# COMPUTE_CLUSTER_J7AHP0_MSMC_ECC_AGGR0_0_VBUSP_MSMC_ECC_AGGR0_CFG_MSMC_ECC0 register map
Vendor: Texas Instruments
Peripheral module from a debugger description file (folder J7_AHP).
Registers are 32-bit, access not given, reset 0x0 unless marked. A register's access mark holds for its fields unless they carry their own. Offsets are as the file gives them; lines under a group give offsets from that group; [hi:lo] are bit positions; {n}, {i} and the like mark numbered series; 'fields as' and 'values as' point back to an identical list; <NAME> marks a mode.

## COMPUTE_CLUSTER_J7AHP0_MSMC_ECC_AGGR0_0_VBUSP_MSMC_ECC_AGGR0_CFG_MSMC_ECC0
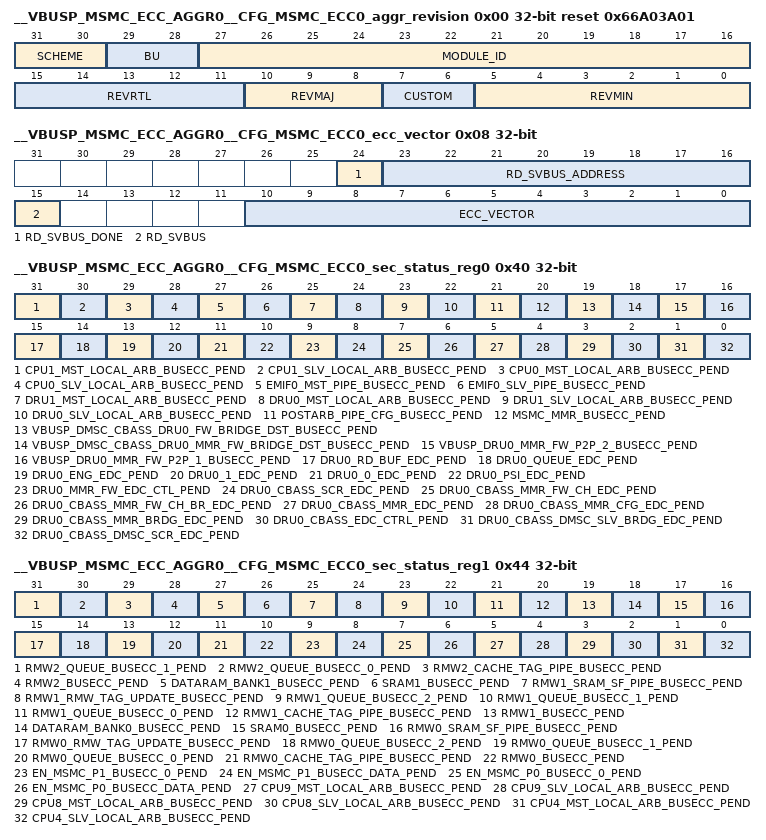
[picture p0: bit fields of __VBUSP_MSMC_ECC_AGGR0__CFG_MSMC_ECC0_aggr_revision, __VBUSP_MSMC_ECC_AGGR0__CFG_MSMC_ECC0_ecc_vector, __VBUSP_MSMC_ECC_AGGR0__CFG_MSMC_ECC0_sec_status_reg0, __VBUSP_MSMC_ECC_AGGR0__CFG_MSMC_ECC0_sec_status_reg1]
0x00 __VBUSP_MSMC_ECC_AGGR0__CFG_MSMC_ECC0_aggr_revision ro reset 0x66A03A01
  [31:30] SCHEME
  [29:28] BU
  [27:16] MODULE_ID
  [15:11] REVRTL — RTL version
  [10:8] REVMAJ — Major version
  [7:6] CUSTOM — Custom version
  [5:0] REVMIN — Minor version
0x08 __VBUSP_MSMC_ECC_AGGR0__CFG_MSMC_ECC0_ecc_vector
  [24] RD_SVBUS_DONE — Status to indicate if read on serial VBUS is complete, write of any value will clear this bit. (access R/W1TC)
  [23:16] RD_SVBUS_ADDRESS rw — Read address
  [15] RD_SVBUS — Write 1 to trigger a read on the serial VBUS (access R/W1TS)
  [10:0] ECC_VECTOR rw — Value written to select the corresponding ECC RAM for control or status
0x0C __VBUSP_MSMC_ECC_AGGR0__CFG_MSMC_ECC0_misc_status ro reset 0x83
  [10:0] NUM_RAMS — Indicates the number of RAMS serviced by the ECC aggregator
0x10 __VBUSP_MSMC_ECC_AGGR0__CFG_MSMC_ECC0_reserved_svbus rw
  [31:0] DATA — Serial VBUS register data
0x3C __VBUSP_MSMC_ECC_AGGR0__CFG_MSMC_ECC0_sec_eoi_reg
  [0] EOI_WR — EOI Register (access R/W1TS)
0x40 __VBUSP_MSMC_ECC_AGGR0__CFG_MSMC_ECC0_sec_status_reg0
  [31] CPU1_MST_LOCAL_ARB_BUSECC_PEND — Interrupt Pending Status for cpu1_mst_local_arb_busecc_pend (access R/W1TS)
  [30] CPU1_SLV_LOCAL_ARB_BUSECC_PEND — Interrupt Pending Status for cpu1_slv_local_arb_busecc_pend (access R/W1TS)
  [29] CPU0_MST_LOCAL_ARB_BUSECC_PEND — Interrupt Pending Status for cpu0_mst_local_arb_busecc_pend (access R/W1TS)
  [28] CPU0_SLV_LOCAL_ARB_BUSECC_PEND — Interrupt Pending Status for cpu0_slv_local_arb_busecc_pend (access R/W1TS)
  [27] EMIF0_MST_PIPE_BUSECC_PEND — Interrupt Pending Status for emif0_mst_pipe_busecc_pend (access R/W1TS)
  [26] EMIF0_SLV_PIPE_BUSECC_PEND — Interrupt Pending Status for emif0_slv_pipe_busecc_pend (access R/W1TS)
  [25] DRU1_MST_LOCAL_ARB_BUSECC_PEND — Interrupt Pending Status for dru1_mst_local_arb_busecc_pend (access R/W1TS)
  [24] DRU0_MST_LOCAL_ARB_BUSECC_PEND — Interrupt Pending Status for dru0_mst_local_arb_busecc_pend (access R/W1TS)
  [23] DRU1_SLV_LOCAL_ARB_BUSECC_PEND — Interrupt Pending Status for dru1_slv_local_arb_busecc_pend (access R/W1TS)
  [22] DRU0_SLV_LOCAL_ARB_BUSECC_PEND — Interrupt Pending Status for dru0_slv_local_arb_busecc_pend (access R/W1TS)
  [21] POSTARB_PIPE_CFG_BUSECC_PEND — Interrupt Pending Status for postarb_pipe_cfg_busecc_pend (access R/W1TS)
  [20] MSMC_MMR_BUSECC_PEND — Interrupt Pending Status for msmc_mmr_busecc_pend (access R/W1TS)
  [19] VBUSP_DMSC_CBASS_DRU0_FW_BRIDGE_DST_BUSECC_PEND — Interrupt Pending Status for vbusp_dmsc_cbass_dru0_fw_bridge_dst_busecc_pend (access R/W1TS)
  [18] VBUSP_DMSC_CBASS_DRU0_MMR_FW_BRIDGE_DST_BUSECC_PEND — Interrupt Pending Status for vbusp_dmsc_cbass_dru0_mmr_fw_bridge_dst_busecc_pend (access R/W1TS)
  [17] VBUSP_DRU0_MMR_FW_P2P_2_BUSECC_PEND — Interrupt Pending Status for vbusp_dru0_mmr_fw_p2p_2_busecc_pend (access R/W1TS)
  [16] VBUSP_DRU0_MMR_FW_P2P_1_BUSECC_PEND — Interrupt Pending Status for vbusp_dru0_mmr_fw_p2p_1_busecc_pend (access R/W1TS)
  [15] DRU0_RD_BUF_EDC_PEND — Interrupt Pending Status for dru0_rd_buf_edc_pend (access R/W1TS)
  [14] DRU0_QUEUE_EDC_PEND — Interrupt Pending Status for dru0_queue_edc_pend (access R/W1TS)
  [13] DRU0_ENG_EDC_PEND — Interrupt Pending Status for dru0_eng_edc_pend (access R/W1TS)
  [12] DRU0_1_EDC_PEND — Interrupt Pending Status for dru0_1_edc_pend (access R/W1TS)
  [11] DRU0_0_EDC_PEND — Interrupt Pending Status for dru0_0_edc_pend (access R/W1TS)
  [10] DRU0_PSI_EDC_PEND — Interrupt Pending Status for dru0_psi_edc_pend (access R/W1TS)
  [9] DRU0_MMR_FW_EDC_CTL_PEND — Interrupt Pending Status for dru0_mmr_fw_edc_ctl_pend (access R/W1TS)
  [8] DRU0_CBASS_SCR_EDC_PEND — Interrupt Pending Status for dru0_cbass_scr_edc_pend (access R/W1TS)
  [7] DRU0_CBASS_MMR_FW_CH_EDC_PEND — Interrupt Pending Status for dru0_cbass_mmr_fw_ch_edc_pend (access R/W1TS)
  [6] DRU0_CBASS_MMR_FW_CH_BR_EDC_PEND — Interrupt Pending Status for dru0_cbass_mmr_fw_ch_br_edc_pend (access R/W1TS)
  [5] DRU0_CBASS_MMR_EDC_PEND — Interrupt Pending Status for dru0_cbass_mmr_edc_pend (access R/W1TS)
  [4] DRU0_CBASS_MMR_CFG_EDC_PEND — Interrupt Pending Status for dru0_cbass_mmr_cfg_edc_pend (access R/W1TS)
  [3] DRU0_CBASS_MMR_BRDG_EDC_PEND — Interrupt Pending Status for dru0_cbass_mmr_brdg_edc_pend (access R/W1TS)
  [2] DRU0_CBASS_EDC_CTRL_PEND — Interrupt Pending Status for dru0_cbass_edc_ctrl_pend (access R/W1TS)
  [1] DRU0_CBASS_DMSC_SLV_BRDG_EDC_PEND — Interrupt Pending Status for dru0_cbass_dmsc_slv_brdg_edc_pend (access R/W1TS)
  [0] DRU0_CBASS_DMSC_SCR_EDC_PEND — Interrupt Pending Status for dru0_cbass_dmsc_scr_edc_pend (access R/W1TS)
0x44 __VBUSP_MSMC_ECC_AGGR0__CFG_MSMC_ECC0_sec_status_reg1
  [31] RMW2_QUEUE_BUSECC_1_PEND — Interrupt Pending Status for rmw2_queue_busecc_1_pend (access R/W1TS)
  [30] RMW2_QUEUE_BUSECC_0_PEND — Interrupt Pending Status for rmw2_queue_busecc_0_pend (access R/W1TS)
  [29] RMW2_CACHE_TAG_PIPE_BUSECC_PEND — Interrupt Pending Status for rmw2_cache_tag_pipe_busecc_pend (access R/W1TS)
  [28] RMW2_BUSECC_PEND — Interrupt Pending Status for rmw2_busecc_pend (access R/W1TS)
  [27] DATARAM_BANK1_BUSECC_PEND — Interrupt Pending Status for dataram_bank1_busecc_pend (access R/W1TS)
  [26] SRAM1_BUSECC_PEND — Interrupt Pending Status for sram1_busecc_pend (access R/W1TS)
  [25] RMW1_SRAM_SF_PIPE_BUSECC_PEND — Interrupt Pending Status for rmw1_sram_sf_pipe_busecc_pend (access R/W1TS)
  [24] RMW1_RMW_TAG_UPDATE_BUSECC_PEND — Interrupt Pending Status for rmw1_rmw_tag_update_busecc_pend (access R/W1TS)
  [23] RMW1_QUEUE_BUSECC_2_PEND — Interrupt Pending Status for rmw1_queue_busecc_2_pend (access R/W1TS)
  [22] RMW1_QUEUE_BUSECC_1_PEND — Interrupt Pending Status for rmw1_queue_busecc_1_pend (access R/W1TS)
  [21] RMW1_QUEUE_BUSECC_0_PEND — Interrupt Pending Status for rmw1_queue_busecc_0_pend (access R/W1TS)
  [20] RMW1_CACHE_TAG_PIPE_BUSECC_PEND — Interrupt Pending Status for rmw1_cache_tag_pipe_busecc_pend (access R/W1TS)
  [19] RMW1_BUSECC_PEND — Interrupt Pending Status for rmw1_busecc_pend (access R/W1TS)
  [18] DATARAM_BANK0_BUSECC_PEND — Interrupt Pending Status for dataram_bank0_busecc_pend (access R/W1TS)
  [17] SRAM0_BUSECC_PEND — Interrupt Pending Status for sram0_busecc_pend (access R/W1TS)
  [16] RMW0_SRAM_SF_PIPE_BUSECC_PEND — Interrupt Pending Status for rmw0_sram_sf_pipe_busecc_pend (access R/W1TS)
  [15] RMW0_RMW_TAG_UPDATE_BUSECC_PEND — Interrupt Pending Status for rmw0_rmw_tag_update_busecc_pend (access R/W1TS)
  [14] RMW0_QUEUE_BUSECC_2_PEND — Interrupt Pending Status for rmw0_queue_busecc_2_pend (access R/W1TS)
  [13] RMW0_QUEUE_BUSECC_1_PEND — Interrupt Pending Status for rmw0_queue_busecc_1_pend (access R/W1TS)
  [12] RMW0_QUEUE_BUSECC_0_PEND — Interrupt Pending Status for rmw0_queue_busecc_0_pend (access R/W1TS)
  [11] RMW0_CACHE_TAG_PIPE_BUSECC_PEND — Interrupt Pending Status for rmw0_cache_tag_pipe_busecc_pend (access R/W1TS)
  [10] RMW0_BUSECC_PEND — Interrupt Pending Status for rmw0_busecc_pend (access R/W1TS)
  [9] EN_MSMC_P1_BUSECC_0_PEND — Interrupt Pending Status for en_msmc_p1_busecc_0_pend (access R/W1TS)
  [8] EN_MSMC_P1_BUSECC_DATA_PEND — Interrupt Pending Status for en_msmc_p1_busecc_data_pend (access R/W1TS)
  [7] EN_MSMC_P0_BUSECC_0_PEND — Interrupt Pending Status for en_msmc_p0_busecc_0_pend (access R/W1TS)
  [6] EN_MSMC_P0_BUSECC_DATA_PEND — Interrupt Pending Status for en_msmc_p0_busecc_data_pend (access R/W1TS)
  [5] CPU9_MST_LOCAL_ARB_BUSECC_PEND — Interrupt Pending Status for cpu9_mst_local_arb_busecc_pend (access R/W1TS)
  [4] CPU9_SLV_LOCAL_ARB_BUSECC_PEND — Interrupt Pending Status for cpu9_slv_local_arb_busecc_pend (access R/W1TS)
  [3] CPU8_MST_LOCAL_ARB_BUSECC_PEND — Interrupt Pending Status for cpu8_mst_local_arb_busecc_pend (access R/W1TS)
  [2] CPU8_SLV_LOCAL_ARB_BUSECC_PEND — Interrupt Pending Status for cpu8_slv_local_arb_busecc_pend (access R/W1TS)
  [1] CPU4_MST_LOCAL_ARB_BUSECC_PEND — Interrupt Pending Status for cpu4_mst_local_arb_busecc_pend (access R/W1TS)
  [0] CPU4_SLV_LOCAL_ARB_BUSECC_PEND — Interrupt Pending Status for cpu4_slv_local_arb_busecc_pend (access R/W1TS)
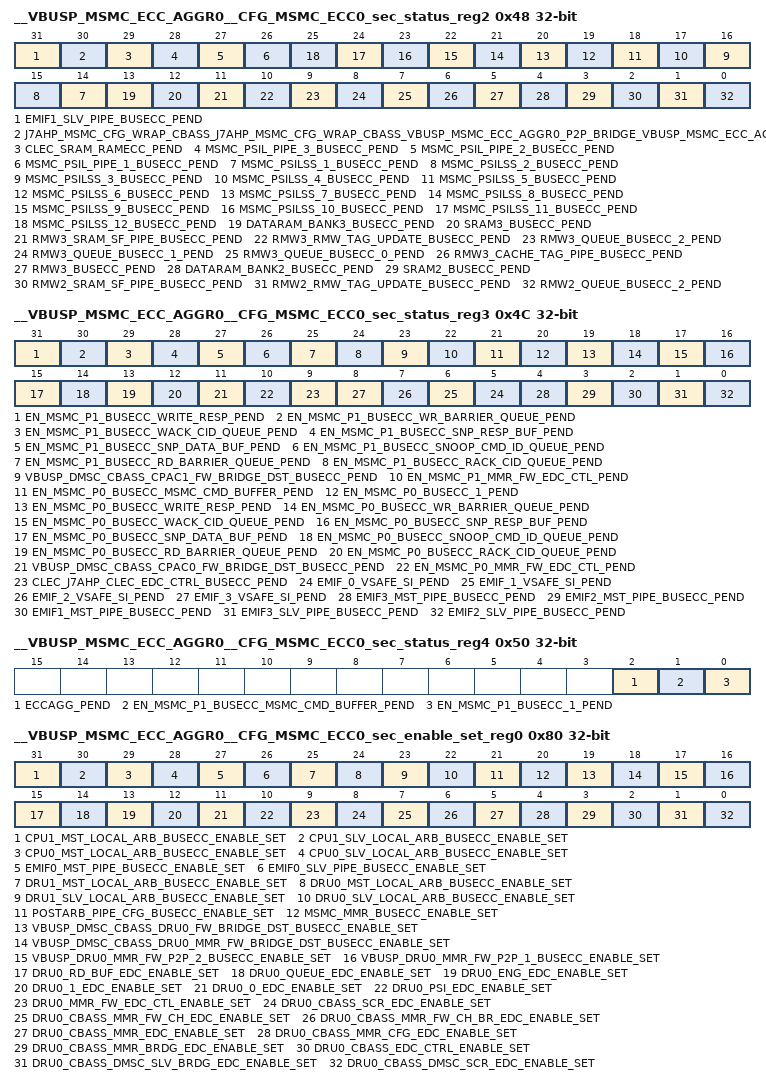
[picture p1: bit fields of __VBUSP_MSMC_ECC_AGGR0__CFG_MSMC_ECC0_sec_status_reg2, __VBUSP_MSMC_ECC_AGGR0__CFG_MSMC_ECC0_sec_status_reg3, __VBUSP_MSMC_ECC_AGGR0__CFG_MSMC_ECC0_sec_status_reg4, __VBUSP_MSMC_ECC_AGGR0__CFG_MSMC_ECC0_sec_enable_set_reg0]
0x48 __VBUSP_MSMC_ECC_AGGR0__CFG_MSMC_ECC0_sec_status_reg2
  [31] EMIF1_SLV_PIPE_BUSECC_PEND — Interrupt Pending Status for emif1_slv_pipe_busecc_pend (access R/W1TS)
  [30] J7AHP_MSMC_CFG_WRAP_CBASS_J7AHP_MSMC_CFG_WRAP_CBASS_VBUSP_MSMC_ECC_AGGR0_P2P_BRIDGE_VBUSP_MSMC_ECC_AGGR0_BRIDGE_DST_BUSECC_PEND — Interrupt Pending Status for j7ahp_msmc_cfg_wrap_cbass_j7ahp_msmc_cfg_wrap_cbass_vbusp_msmc_ecc_aggr0_p2p_bridge_vbusp_msmc_ecc_aggr0_bridge_dst_busecc_pend (access R/W1TS)
  [29] CLEC_SRAM_RAMECC_PEND — Interrupt Pending Status for clec_sram_ramecc_pend (access R/W1TS)
  [28] MSMC_PSIL_PIPE_3_BUSECC_PEND — Interrupt Pending Status for msmc_psil_pipe_3_busecc_pend (access R/W1TS)
  [27] MSMC_PSIL_PIPE_2_BUSECC_PEND — Interrupt Pending Status for msmc_psil_pipe_2_busecc_pend (access R/W1TS)
  [26] MSMC_PSIL_PIPE_1_BUSECC_PEND — Interrupt Pending Status for msmc_psil_pipe_1_busecc_pend (access R/W1TS)
  [n+13] MSMC_PSILSS_{n}_BUSECC_PEND (n=1..12) — Interrupt Pending Status for msmc_psilss_{n}_busecc_pend (access R/W1TS)
  [13] DATARAM_BANK3_BUSECC_PEND — Interrupt Pending Status for dataram_bank3_busecc_pend (access R/W1TS)
  [12] SRAM3_BUSECC_PEND — Interrupt Pending Status for sram3_busecc_pend (access R/W1TS)
  [11] RMW3_SRAM_SF_PIPE_BUSECC_PEND — Interrupt Pending Status for rmw3_sram_sf_pipe_busecc_pend (access R/W1TS)
  [10] RMW3_RMW_TAG_UPDATE_BUSECC_PEND — Interrupt Pending Status for rmw3_rmw_tag_update_busecc_pend (access R/W1TS)
  [9] RMW3_QUEUE_BUSECC_2_PEND — Interrupt Pending Status for rmw3_queue_busecc_2_pend (access R/W1TS)
  [8] RMW3_QUEUE_BUSECC_1_PEND — Interrupt Pending Status for rmw3_queue_busecc_1_pend (access R/W1TS)
  [7] RMW3_QUEUE_BUSECC_0_PEND — Interrupt Pending Status for rmw3_queue_busecc_0_pend (access R/W1TS)
  [6] RMW3_CACHE_TAG_PIPE_BUSECC_PEND — Interrupt Pending Status for rmw3_cache_tag_pipe_busecc_pend (access R/W1TS)
  [5] RMW3_BUSECC_PEND — Interrupt Pending Status for rmw3_busecc_pend (access R/W1TS)
  [4] DATARAM_BANK2_BUSECC_PEND — Interrupt Pending Status for dataram_bank2_busecc_pend (access R/W1TS)
  [3] SRAM2_BUSECC_PEND — Interrupt Pending Status for sram2_busecc_pend (access R/W1TS)
  [2] RMW2_SRAM_SF_PIPE_BUSECC_PEND — Interrupt Pending Status for rmw2_sram_sf_pipe_busecc_pend (access R/W1TS)
  [1] RMW2_RMW_TAG_UPDATE_BUSECC_PEND — Interrupt Pending Status for rmw2_rmw_tag_update_busecc_pend (access R/W1TS)
  [0] RMW2_QUEUE_BUSECC_2_PEND — Interrupt Pending Status for rmw2_queue_busecc_2_pend (access R/W1TS)
0x4C __VBUSP_MSMC_ECC_AGGR0__CFG_MSMC_ECC0_sec_status_reg3
  [31] EN_MSMC_P1_BUSECC_WRITE_RESP_PEND — Interrupt Pending Status for en_msmc_p1_busecc_write_resp_pend (access R/W1TS)
  [30] EN_MSMC_P1_BUSECC_WR_BARRIER_QUEUE_PEND — Interrupt Pending Status for en_msmc_p1_busecc_wr_barrier_queue_pend (access R/W1TS)
  [29] EN_MSMC_P1_BUSECC_WACK_CID_QUEUE_PEND — Interrupt Pending Status for en_msmc_p1_busecc_wack_cid_queue_pend (access R/W1TS)
  [28] EN_MSMC_P1_BUSECC_SNP_RESP_BUF_PEND — Interrupt Pending Status for en_msmc_p1_busecc_snp_resp_buf_pend (access R/W1TS)
  [27] EN_MSMC_P1_BUSECC_SNP_DATA_BUF_PEND — Interrupt Pending Status for en_msmc_p1_busecc_snp_data_buf_pend (access R/W1TS)
  [26] EN_MSMC_P1_BUSECC_SNOOP_CMD_ID_QUEUE_PEND — Interrupt Pending Status for en_msmc_p1_busecc_snoop_cmd_id_queue_pend (access R/W1TS)
  [25] EN_MSMC_P1_BUSECC_RD_BARRIER_QUEUE_PEND — Interrupt Pending Status for en_msmc_p1_busecc_rd_barrier_queue_pend (access R/W1TS)
  [24] EN_MSMC_P1_BUSECC_RACK_CID_QUEUE_PEND — Interrupt Pending Status for en_msmc_p1_busecc_rack_cid_queue_pend (access R/W1TS)
  [23] VBUSP_DMSC_CBASS_CPAC1_FW_BRIDGE_DST_BUSECC_PEND — Interrupt Pending Status for vbusp_dmsc_cbass_cpac1_fw_bridge_dst_busecc_pend (access R/W1TS)
  [22] EN_MSMC_P1_MMR_FW_EDC_CTL_PEND — Interrupt Pending Status for en_msmc_p1_mmr_fw_edc_ctl_pend (access R/W1TS)
  [21] EN_MSMC_P0_BUSECC_MSMC_CMD_BUFFER_PEND — Interrupt Pending Status for en_msmc_p0_busecc_msmc_cmd_buffer_pend (access R/W1TS)
  [20] EN_MSMC_P0_BUSECC_1_PEND — Interrupt Pending Status for en_msmc_p0_busecc_1_pend (access R/W1TS)
  [19] EN_MSMC_P0_BUSECC_WRITE_RESP_PEND — Interrupt Pending Status for en_msmc_p0_busecc_write_resp_pend (access R/W1TS)
  [18] EN_MSMC_P0_BUSECC_WR_BARRIER_QUEUE_PEND — Interrupt Pending Status for en_msmc_p0_busecc_wr_barrier_queue_pend (access R/W1TS)
  [17] EN_MSMC_P0_BUSECC_WACK_CID_QUEUE_PEND — Interrupt Pending Status for en_msmc_p0_busecc_wack_cid_queue_pend (access R/W1TS)
  [16] EN_MSMC_P0_BUSECC_SNP_RESP_BUF_PEND — Interrupt Pending Status for en_msmc_p0_busecc_snp_resp_buf_pend (access R/W1TS)
  [15] EN_MSMC_P0_BUSECC_SNP_DATA_BUF_PEND — Interrupt Pending Status for en_msmc_p0_busecc_snp_data_buf_pend (access R/W1TS)
  [14] EN_MSMC_P0_BUSECC_SNOOP_CMD_ID_QUEUE_PEND — Interrupt Pending Status for en_msmc_p0_busecc_snoop_cmd_id_queue_pend (access R/W1TS)
  [13] EN_MSMC_P0_BUSECC_RD_BARRIER_QUEUE_PEND — Interrupt Pending Status for en_msmc_p0_busecc_rd_barrier_queue_pend (access R/W1TS)
  [12] EN_MSMC_P0_BUSECC_RACK_CID_QUEUE_PEND — Interrupt Pending Status for en_msmc_p0_busecc_rack_cid_queue_pend (access R/W1TS)
  [11] VBUSP_DMSC_CBASS_CPAC0_FW_BRIDGE_DST_BUSECC_PEND — Interrupt Pending Status for vbusp_dmsc_cbass_cpac0_fw_bridge_dst_busecc_pend (access R/W1TS)
  [10] EN_MSMC_P0_MMR_FW_EDC_CTL_PEND — Interrupt Pending Status for en_msmc_p0_mmr_fw_edc_ctl_pend (access R/W1TS)
  [9] CLEC_J7AHP_CLEC_EDC_CTRL_BUSECC_PEND — Interrupt Pending Status for clec_j7ahp_clec_edc_ctrl_busecc_pend (access R/W1TS)
  [n+5] EMIF_{n}_VSAFE_SI_PEND (n=0..3) — Interrupt Pending Status for emif_{n}_vsafe_si_pend (access R/W1TS)
  [4] EMIF3_MST_PIPE_BUSECC_PEND — Interrupt Pending Status for emif3_mst_pipe_busecc_pend (access R/W1TS)
  [3] EMIF2_MST_PIPE_BUSECC_PEND — Interrupt Pending Status for emif2_mst_pipe_busecc_pend (access R/W1TS)
  [2] EMIF1_MST_PIPE_BUSECC_PEND — Interrupt Pending Status for emif1_mst_pipe_busecc_pend (access R/W1TS)
  [1] EMIF3_SLV_PIPE_BUSECC_PEND — Interrupt Pending Status for emif3_slv_pipe_busecc_pend (access R/W1TS)
  [0] EMIF2_SLV_PIPE_BUSECC_PEND — Interrupt Pending Status for emif2_slv_pipe_busecc_pend (access R/W1TS)
0x50 __VBUSP_MSMC_ECC_AGGR0__CFG_MSMC_ECC0_sec_status_reg4
  [2] ECCAGG_PEND — Interrupt Pending Status for eccagg_pend (access R/W1TS)
  [1] EN_MSMC_P1_BUSECC_MSMC_CMD_BUFFER_PEND — Interrupt Pending Status for en_msmc_p1_busecc_msmc_cmd_buffer_pend (access R/W1TS)
  [0] EN_MSMC_P1_BUSECC_1_PEND — Interrupt Pending Status for en_msmc_p1_busecc_1_pend (access R/W1TS)
0x80 __VBUSP_MSMC_ECC_AGGR0__CFG_MSMC_ECC0_sec_enable_set_reg0
  [31] CPU1_MST_LOCAL_ARB_BUSECC_ENABLE_SET — Interrupt Enable Set Register for cpu1_mst_local_arb_busecc_pend (access R/W1TS)
  [30] CPU1_SLV_LOCAL_ARB_BUSECC_ENABLE_SET — Interrupt Enable Set Register for cpu1_slv_local_arb_busecc_pend (access R/W1TS)
  [29] CPU0_MST_LOCAL_ARB_BUSECC_ENABLE_SET — Interrupt Enable Set Register for cpu0_mst_local_arb_busecc_pend (access R/W1TS)
  [28] CPU0_SLV_LOCAL_ARB_BUSECC_ENABLE_SET — Interrupt Enable Set Register for cpu0_slv_local_arb_busecc_pend (access R/W1TS)
  [27] EMIF0_MST_PIPE_BUSECC_ENABLE_SET — Interrupt Enable Set Register for emif0_mst_pipe_busecc_pend (access R/W1TS)
  [26] EMIF0_SLV_PIPE_BUSECC_ENABLE_SET — Interrupt Enable Set Register for emif0_slv_pipe_busecc_pend (access R/W1TS)
  [25] DRU1_MST_LOCAL_ARB_BUSECC_ENABLE_SET — Interrupt Enable Set Register for dru1_mst_local_arb_busecc_pend (access R/W1TS)
  [24] DRU0_MST_LOCAL_ARB_BUSECC_ENABLE_SET — Interrupt Enable Set Register for dru0_mst_local_arb_busecc_pend (access R/W1TS)
  [23] DRU1_SLV_LOCAL_ARB_BUSECC_ENABLE_SET — Interrupt Enable Set Register for dru1_slv_local_arb_busecc_pend (access R/W1TS)
  [22] DRU0_SLV_LOCAL_ARB_BUSECC_ENABLE_SET — Interrupt Enable Set Register for dru0_slv_local_arb_busecc_pend (access R/W1TS)
  [21] POSTARB_PIPE_CFG_BUSECC_ENABLE_SET — Interrupt Enable Set Register for postarb_pipe_cfg_busecc_pend (access R/W1TS)
  [20] MSMC_MMR_BUSECC_ENABLE_SET — Interrupt Enable Set Register for msmc_mmr_busecc_pend (access R/W1TS)
  [19] VBUSP_DMSC_CBASS_DRU0_FW_BRIDGE_DST_BUSECC_ENABLE_SET — Interrupt Enable Set Register for vbusp_dmsc_cbass_dru0_fw_bridge_dst_busecc_pend (access R/W1TS)
  [18] VBUSP_DMSC_CBASS_DRU0_MMR_FW_BRIDGE_DST_BUSECC_ENABLE_SET — Interrupt Enable Set Register for vbusp_dmsc_cbass_dru0_mmr_fw_bridge_dst_busecc_pend (access R/W1TS)
  [17] VBUSP_DRU0_MMR_FW_P2P_2_BUSECC_ENABLE_SET — Interrupt Enable Set Register for vbusp_dru0_mmr_fw_p2p_2_busecc_pend (access R/W1TS)
  [16] VBUSP_DRU0_MMR_FW_P2P_1_BUSECC_ENABLE_SET — Interrupt Enable Set Register for vbusp_dru0_mmr_fw_p2p_1_busecc_pend (access R/W1TS)
  [15] DRU0_RD_BUF_EDC_ENABLE_SET — Interrupt Enable Set Register for dru0_rd_buf_edc_pend (access R/W1TS)
  [14] DRU0_QUEUE_EDC_ENABLE_SET — Interrupt Enable Set Register for dru0_queue_edc_pend (access R/W1TS)
  [13] DRU0_ENG_EDC_ENABLE_SET — Interrupt Enable Set Register for dru0_eng_edc_pend (access R/W1TS)
  [12] DRU0_1_EDC_ENABLE_SET — Interrupt Enable Set Register for dru0_1_edc_pend (access R/W1TS)
  [11] DRU0_0_EDC_ENABLE_SET — Interrupt Enable Set Register for dru0_0_edc_pend (access R/W1TS)
  [10] DRU0_PSI_EDC_ENABLE_SET — Interrupt Enable Set Register for dru0_psi_edc_pend (access R/W1TS)
  [9] DRU0_MMR_FW_EDC_CTL_ENABLE_SET — Interrupt Enable Set Register for dru0_mmr_fw_edc_ctl_pend (access R/W1TS)
  [8] DRU0_CBASS_SCR_EDC_ENABLE_SET — Interrupt Enable Set Register for dru0_cbass_scr_edc_pend (access R/W1TS)
  [7] DRU0_CBASS_MMR_FW_CH_EDC_ENABLE_SET — Interrupt Enable Set Register for dru0_cbass_mmr_fw_ch_edc_pend (access R/W1TS)
  [6] DRU0_CBASS_MMR_FW_CH_BR_EDC_ENABLE_SET — Interrupt Enable Set Register for dru0_cbass_mmr_fw_ch_br_edc_pend (access R/W1TS)
  [5] DRU0_CBASS_MMR_EDC_ENABLE_SET — Interrupt Enable Set Register for dru0_cbass_mmr_edc_pend (access R/W1TS)
  [4] DRU0_CBASS_MMR_CFG_EDC_ENABLE_SET — Interrupt Enable Set Register for dru0_cbass_mmr_cfg_edc_pend (access R/W1TS)
  [3] DRU0_CBASS_MMR_BRDG_EDC_ENABLE_SET — Interrupt Enable Set Register for dru0_cbass_mmr_brdg_edc_pend (access R/W1TS)
  [2] DRU0_CBASS_EDC_CTRL_ENABLE_SET — Interrupt Enable Set Register for dru0_cbass_edc_ctrl_pend (access R/W1TS)
  [1] DRU0_CBASS_DMSC_SLV_BRDG_EDC_ENABLE_SET — Interrupt Enable Set Register for dru0_cbass_dmsc_slv_brdg_edc_pend (access R/W1TS)
  [0] DRU0_CBASS_DMSC_SCR_EDC_ENABLE_SET — Interrupt Enable Set Register for dru0_cbass_dmsc_scr_edc_pend (access R/W1TS)
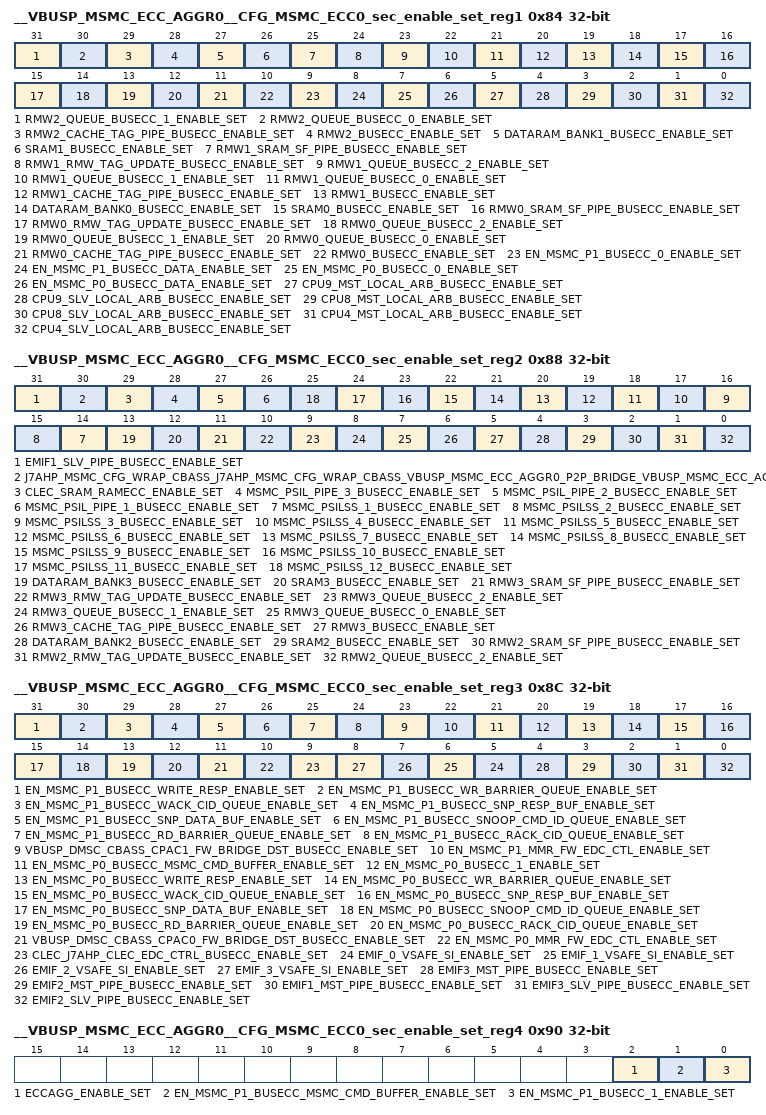
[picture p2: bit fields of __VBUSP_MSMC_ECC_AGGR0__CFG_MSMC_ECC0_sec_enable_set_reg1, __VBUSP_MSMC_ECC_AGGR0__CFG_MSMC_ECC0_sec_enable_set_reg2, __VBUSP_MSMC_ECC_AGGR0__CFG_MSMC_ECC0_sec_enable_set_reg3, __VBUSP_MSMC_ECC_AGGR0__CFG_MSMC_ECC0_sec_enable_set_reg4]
0x84 __VBUSP_MSMC_ECC_AGGR0__CFG_MSMC_ECC0_sec_enable_set_reg1
  [31] RMW2_QUEUE_BUSECC_1_ENABLE_SET — Interrupt Enable Set Register for rmw2_queue_busecc_1_pend (access R/W1TS)
  [30] RMW2_QUEUE_BUSECC_0_ENABLE_SET — Interrupt Enable Set Register for rmw2_queue_busecc_0_pend (access R/W1TS)
  [29] RMW2_CACHE_TAG_PIPE_BUSECC_ENABLE_SET — Interrupt Enable Set Register for rmw2_cache_tag_pipe_busecc_pend (access R/W1TS)
  [28] RMW2_BUSECC_ENABLE_SET — Interrupt Enable Set Register for rmw2_busecc_pend (access R/W1TS)
  [27] DATARAM_BANK1_BUSECC_ENABLE_SET — Interrupt Enable Set Register for dataram_bank1_busecc_pend (access R/W1TS)
  [26] SRAM1_BUSECC_ENABLE_SET — Interrupt Enable Set Register for sram1_busecc_pend (access R/W1TS)
  [25] RMW1_SRAM_SF_PIPE_BUSECC_ENABLE_SET — Interrupt Enable Set Register for rmw1_sram_sf_pipe_busecc_pend (access R/W1TS)
  [24] RMW1_RMW_TAG_UPDATE_BUSECC_ENABLE_SET — Interrupt Enable Set Register for rmw1_rmw_tag_update_busecc_pend (access R/W1TS)
  [23] RMW1_QUEUE_BUSECC_2_ENABLE_SET — Interrupt Enable Set Register for rmw1_queue_busecc_2_pend (access R/W1TS)
  [22] RMW1_QUEUE_BUSECC_1_ENABLE_SET — Interrupt Enable Set Register for rmw1_queue_busecc_1_pend (access R/W1TS)
  [21] RMW1_QUEUE_BUSECC_0_ENABLE_SET — Interrupt Enable Set Register for rmw1_queue_busecc_0_pend (access R/W1TS)
  [20] RMW1_CACHE_TAG_PIPE_BUSECC_ENABLE_SET — Interrupt Enable Set Register for rmw1_cache_tag_pipe_busecc_pend (access R/W1TS)
  [19] RMW1_BUSECC_ENABLE_SET — Interrupt Enable Set Register for rmw1_busecc_pend (access R/W1TS)
  [18] DATARAM_BANK0_BUSECC_ENABLE_SET — Interrupt Enable Set Register for dataram_bank0_busecc_pend (access R/W1TS)
  [17] SRAM0_BUSECC_ENABLE_SET — Interrupt Enable Set Register for sram0_busecc_pend (access R/W1TS)
  [16] RMW0_SRAM_SF_PIPE_BUSECC_ENABLE_SET — Interrupt Enable Set Register for rmw0_sram_sf_pipe_busecc_pend (access R/W1TS)
  [15] RMW0_RMW_TAG_UPDATE_BUSECC_ENABLE_SET — Interrupt Enable Set Register for rmw0_rmw_tag_update_busecc_pend (access R/W1TS)
  [14] RMW0_QUEUE_BUSECC_2_ENABLE_SET — Interrupt Enable Set Register for rmw0_queue_busecc_2_pend (access R/W1TS)
  [13] RMW0_QUEUE_BUSECC_1_ENABLE_SET — Interrupt Enable Set Register for rmw0_queue_busecc_1_pend (access R/W1TS)
  [12] RMW0_QUEUE_BUSECC_0_ENABLE_SET — Interrupt Enable Set Register for rmw0_queue_busecc_0_pend (access R/W1TS)
  [11] RMW0_CACHE_TAG_PIPE_BUSECC_ENABLE_SET — Interrupt Enable Set Register for rmw0_cache_tag_pipe_busecc_pend (access R/W1TS)
  [10] RMW0_BUSECC_ENABLE_SET — Interrupt Enable Set Register for rmw0_busecc_pend (access R/W1TS)
  [9] EN_MSMC_P1_BUSECC_0_ENABLE_SET — Interrupt Enable Set Register for en_msmc_p1_busecc_0_pend (access R/W1TS)
  [8] EN_MSMC_P1_BUSECC_DATA_ENABLE_SET — Interrupt Enable Set Register for en_msmc_p1_busecc_data_pend (access R/W1TS)
  [7] EN_MSMC_P0_BUSECC_0_ENABLE_SET — Interrupt Enable Set Register for en_msmc_p0_busecc_0_pend (access R/W1TS)
  [6] EN_MSMC_P0_BUSECC_DATA_ENABLE_SET — Interrupt Enable Set Register for en_msmc_p0_busecc_data_pend (access R/W1TS)
  [5] CPU9_MST_LOCAL_ARB_BUSECC_ENABLE_SET — Interrupt Enable Set Register for cpu9_mst_local_arb_busecc_pend (access R/W1TS)
  [4] CPU9_SLV_LOCAL_ARB_BUSECC_ENABLE_SET — Interrupt Enable Set Register for cpu9_slv_local_arb_busecc_pend (access R/W1TS)
  [3] CPU8_MST_LOCAL_ARB_BUSECC_ENABLE_SET — Interrupt Enable Set Register for cpu8_mst_local_arb_busecc_pend (access R/W1TS)
  [2] CPU8_SLV_LOCAL_ARB_BUSECC_ENABLE_SET — Interrupt Enable Set Register for cpu8_slv_local_arb_busecc_pend (access R/W1TS)
  [1] CPU4_MST_LOCAL_ARB_BUSECC_ENABLE_SET — Interrupt Enable Set Register for cpu4_mst_local_arb_busecc_pend (access R/W1TS)
  [0] CPU4_SLV_LOCAL_ARB_BUSECC_ENABLE_SET — Interrupt Enable Set Register for cpu4_slv_local_arb_busecc_pend (access R/W1TS)
0x88 __VBUSP_MSMC_ECC_AGGR0__CFG_MSMC_ECC0_sec_enable_set_reg2
  [31] EMIF1_SLV_PIPE_BUSECC_ENABLE_SET — Interrupt Enable Set Register for emif1_slv_pipe_busecc_pend (access R/W1TS)
  [30] J7AHP_MSMC_CFG_WRAP_CBASS_J7AHP_MSMC_CFG_WRAP_CBASS_VBUSP_MSMC_ECC_AGGR0_P2P_BRIDGE_VBUSP_MSMC_ECC_AGGR0_BRIDGE_DST_BUSECC_ENABLE_SET — Interrupt Enable Set Register for j7ahp_msmc_cfg_wrap_cbass_j7ahp_msmc_cfg_wrap_cbass_vbusp_msmc_ecc_aggr0_p2p_bridge_vbusp_msmc_ecc_aggr0_bridge_dst_busecc_pend (access R/W1TS)
  [29] CLEC_SRAM_RAMECC_ENABLE_SET — Interrupt Enable Set Register for clec_sram_ramecc_pend (access R/W1TS)
  [28] MSMC_PSIL_PIPE_3_BUSECC_ENABLE_SET — Interrupt Enable Set Register for msmc_psil_pipe_3_busecc_pend (access R/W1TS)
  [27] MSMC_PSIL_PIPE_2_BUSECC_ENABLE_SET — Interrupt Enable Set Register for msmc_psil_pipe_2_busecc_pend (access R/W1TS)
  [26] MSMC_PSIL_PIPE_1_BUSECC_ENABLE_SET — Interrupt Enable Set Register for msmc_psil_pipe_1_busecc_pend (access R/W1TS)
  [n+13] MSMC_PSILSS_{n}_BUSECC_ENABLE_SET (n=1..12) — Interrupt Enable Set Register for msmc_psilss_{n}_busecc_pend (access R/W1TS)
  [13] DATARAM_BANK3_BUSECC_ENABLE_SET — Interrupt Enable Set Register for dataram_bank3_busecc_pend (access R/W1TS)
  [12] SRAM3_BUSECC_ENABLE_SET — Interrupt Enable Set Register for sram3_busecc_pend (access R/W1TS)
  [11] RMW3_SRAM_SF_PIPE_BUSECC_ENABLE_SET — Interrupt Enable Set Register for rmw3_sram_sf_pipe_busecc_pend (access R/W1TS)
  [10] RMW3_RMW_TAG_UPDATE_BUSECC_ENABLE_SET — Interrupt Enable Set Register for rmw3_rmw_tag_update_busecc_pend (access R/W1TS)
  [9] RMW3_QUEUE_BUSECC_2_ENABLE_SET — Interrupt Enable Set Register for rmw3_queue_busecc_2_pend (access R/W1TS)
  [8] RMW3_QUEUE_BUSECC_1_ENABLE_SET — Interrupt Enable Set Register for rmw3_queue_busecc_1_pend (access R/W1TS)
  [7] RMW3_QUEUE_BUSECC_0_ENABLE_SET — Interrupt Enable Set Register for rmw3_queue_busecc_0_pend (access R/W1TS)
  [6] RMW3_CACHE_TAG_PIPE_BUSECC_ENABLE_SET — Interrupt Enable Set Register for rmw3_cache_tag_pipe_busecc_pend (access R/W1TS)
  [5] RMW3_BUSECC_ENABLE_SET — Interrupt Enable Set Register for rmw3_busecc_pend (access R/W1TS)
  [4] DATARAM_BANK2_BUSECC_ENABLE_SET — Interrupt Enable Set Register for dataram_bank2_busecc_pend (access R/W1TS)
  [3] SRAM2_BUSECC_ENABLE_SET — Interrupt Enable Set Register for sram2_busecc_pend (access R/W1TS)
  [2] RMW2_SRAM_SF_PIPE_BUSECC_ENABLE_SET — Interrupt Enable Set Register for rmw2_sram_sf_pipe_busecc_pend (access R/W1TS)
  [1] RMW2_RMW_TAG_UPDATE_BUSECC_ENABLE_SET — Interrupt Enable Set Register for rmw2_rmw_tag_update_busecc_pend (access R/W1TS)
  [0] RMW2_QUEUE_BUSECC_2_ENABLE_SET — Interrupt Enable Set Register for rmw2_queue_busecc_2_pend (access R/W1TS)
0x8C __VBUSP_MSMC_ECC_AGGR0__CFG_MSMC_ECC0_sec_enable_set_reg3
  [31] EN_MSMC_P1_BUSECC_WRITE_RESP_ENABLE_SET — Interrupt Enable Set Register for en_msmc_p1_busecc_write_resp_pend (access R/W1TS)
  [30] EN_MSMC_P1_BUSECC_WR_BARRIER_QUEUE_ENABLE_SET — Interrupt Enable Set Register for en_msmc_p1_busecc_wr_barrier_queue_pend (access R/W1TS)
  [29] EN_MSMC_P1_BUSECC_WACK_CID_QUEUE_ENABLE_SET — Interrupt Enable Set Register for en_msmc_p1_busecc_wack_cid_queue_pend (access R/W1TS)
  [28] EN_MSMC_P1_BUSECC_SNP_RESP_BUF_ENABLE_SET — Interrupt Enable Set Register for en_msmc_p1_busecc_snp_resp_buf_pend (access R/W1TS)
  [27] EN_MSMC_P1_BUSECC_SNP_DATA_BUF_ENABLE_SET — Interrupt Enable Set Register for en_msmc_p1_busecc_snp_data_buf_pend (access R/W1TS)
  [26] EN_MSMC_P1_BUSECC_SNOOP_CMD_ID_QUEUE_ENABLE_SET — Interrupt Enable Set Register for en_msmc_p1_busecc_snoop_cmd_id_queue_pend (access R/W1TS)
  [25] EN_MSMC_P1_BUSECC_RD_BARRIER_QUEUE_ENABLE_SET — Interrupt Enable Set Register for en_msmc_p1_busecc_rd_barrier_queue_pend (access R/W1TS)
  [24] EN_MSMC_P1_BUSECC_RACK_CID_QUEUE_ENABLE_SET — Interrupt Enable Set Register for en_msmc_p1_busecc_rack_cid_queue_pend (access R/W1TS)
  [23] VBUSP_DMSC_CBASS_CPAC1_FW_BRIDGE_DST_BUSECC_ENABLE_SET — Interrupt Enable Set Register for vbusp_dmsc_cbass_cpac1_fw_bridge_dst_busecc_pend (access R/W1TS)
  [22] EN_MSMC_P1_MMR_FW_EDC_CTL_ENABLE_SET — Interrupt Enable Set Register for en_msmc_p1_mmr_fw_edc_ctl_pend (access R/W1TS)
  [21] EN_MSMC_P0_BUSECC_MSMC_CMD_BUFFER_ENABLE_SET — Interrupt Enable Set Register for en_msmc_p0_busecc_msmc_cmd_buffer_pend (access R/W1TS)
  [20] EN_MSMC_P0_BUSECC_1_ENABLE_SET — Interrupt Enable Set Register for en_msmc_p0_busecc_1_pend (access R/W1TS)
  [19] EN_MSMC_P0_BUSECC_WRITE_RESP_ENABLE_SET — Interrupt Enable Set Register for en_msmc_p0_busecc_write_resp_pend (access R/W1TS)
  [18] EN_MSMC_P0_BUSECC_WR_BARRIER_QUEUE_ENABLE_SET — Interrupt Enable Set Register for en_msmc_p0_busecc_wr_barrier_queue_pend (access R/W1TS)
  [17] EN_MSMC_P0_BUSECC_WACK_CID_QUEUE_ENABLE_SET — Interrupt Enable Set Register for en_msmc_p0_busecc_wack_cid_queue_pend (access R/W1TS)
  [16] EN_MSMC_P0_BUSECC_SNP_RESP_BUF_ENABLE_SET — Interrupt Enable Set Register for en_msmc_p0_busecc_snp_resp_buf_pend (access R/W1TS)
  [15] EN_MSMC_P0_BUSECC_SNP_DATA_BUF_ENABLE_SET — Interrupt Enable Set Register for en_msmc_p0_busecc_snp_data_buf_pend (access R/W1TS)
  [14] EN_MSMC_P0_BUSECC_SNOOP_CMD_ID_QUEUE_ENABLE_SET — Interrupt Enable Set Register for en_msmc_p0_busecc_snoop_cmd_id_queue_pend (access R/W1TS)
  [13] EN_MSMC_P0_BUSECC_RD_BARRIER_QUEUE_ENABLE_SET — Interrupt Enable Set Register for en_msmc_p0_busecc_rd_barrier_queue_pend (access R/W1TS)
  [12] EN_MSMC_P0_BUSECC_RACK_CID_QUEUE_ENABLE_SET — Interrupt Enable Set Register for en_msmc_p0_busecc_rack_cid_queue_pend (access R/W1TS)
  [11] VBUSP_DMSC_CBASS_CPAC0_FW_BRIDGE_DST_BUSECC_ENABLE_SET — Interrupt Enable Set Register for vbusp_dmsc_cbass_cpac0_fw_bridge_dst_busecc_pend (access R/W1TS)
  [10] EN_MSMC_P0_MMR_FW_EDC_CTL_ENABLE_SET — Interrupt Enable Set Register for en_msmc_p0_mmr_fw_edc_ctl_pend (access R/W1TS)
  [9] CLEC_J7AHP_CLEC_EDC_CTRL_BUSECC_ENABLE_SET — Interrupt Enable Set Register for clec_j7ahp_clec_edc_ctrl_busecc_pend (access R/W1TS)
  [n+5] EMIF_{n}_VSAFE_SI_ENABLE_SET (n=0..3) — Interrupt Enable Set Register for emif_{n}_vsafe_si_pend (access R/W1TS)
  [4] EMIF3_MST_PIPE_BUSECC_ENABLE_SET — Interrupt Enable Set Register for emif3_mst_pipe_busecc_pend (access R/W1TS)
  [3] EMIF2_MST_PIPE_BUSECC_ENABLE_SET — Interrupt Enable Set Register for emif2_mst_pipe_busecc_pend (access R/W1TS)
  [2] EMIF1_MST_PIPE_BUSECC_ENABLE_SET — Interrupt Enable Set Register for emif1_mst_pipe_busecc_pend (access R/W1TS)
  [1] EMIF3_SLV_PIPE_BUSECC_ENABLE_SET — Interrupt Enable Set Register for emif3_slv_pipe_busecc_pend (access R/W1TS)
  [0] EMIF2_SLV_PIPE_BUSECC_ENABLE_SET — Interrupt Enable Set Register for emif2_slv_pipe_busecc_pend (access R/W1TS)
0x90 __VBUSP_MSMC_ECC_AGGR0__CFG_MSMC_ECC0_sec_enable_set_reg4
  [2] ECCAGG_ENABLE_SET — Interrupt Enable Set Register for eccagg_pend (access R/W1TS)
  [1] EN_MSMC_P1_BUSECC_MSMC_CMD_BUFFER_ENABLE_SET — Interrupt Enable Set Register for en_msmc_p1_busecc_msmc_cmd_buffer_pend (access R/W1TS)
  [0] EN_MSMC_P1_BUSECC_1_ENABLE_SET — Interrupt Enable Set Register for en_msmc_p1_busecc_1_pend (access R/W1TS)
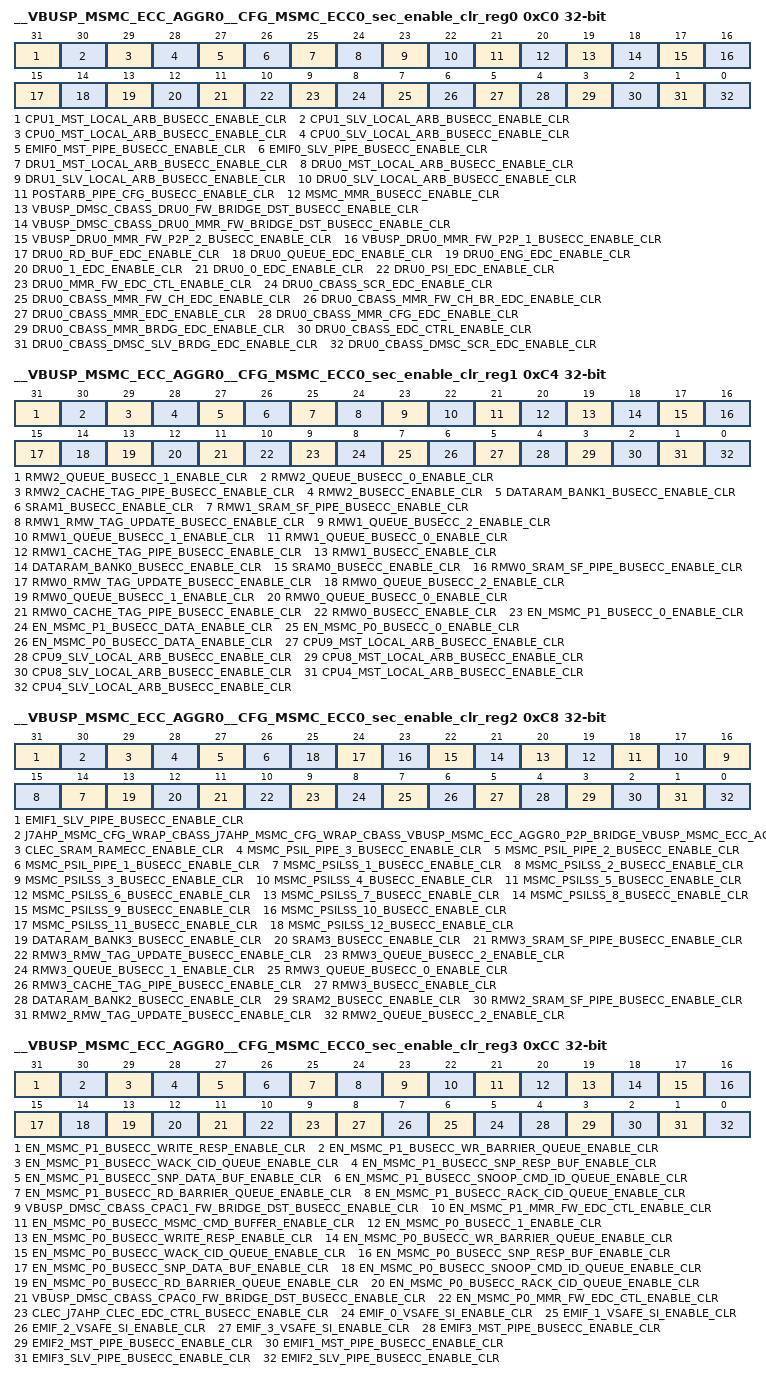
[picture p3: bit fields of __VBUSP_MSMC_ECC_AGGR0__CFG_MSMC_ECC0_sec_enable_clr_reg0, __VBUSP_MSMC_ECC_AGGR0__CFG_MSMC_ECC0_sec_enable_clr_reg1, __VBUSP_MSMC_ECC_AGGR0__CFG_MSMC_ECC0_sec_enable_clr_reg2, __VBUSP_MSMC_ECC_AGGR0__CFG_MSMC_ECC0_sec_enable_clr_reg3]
0xC0 __VBUSP_MSMC_ECC_AGGR0__CFG_MSMC_ECC0_sec_enable_clr_reg0
  [31] CPU1_MST_LOCAL_ARB_BUSECC_ENABLE_CLR — Interrupt Enable Clear Register for cpu1_mst_local_arb_busecc_pend (access R/W1TC)
  [30] CPU1_SLV_LOCAL_ARB_BUSECC_ENABLE_CLR — Interrupt Enable Clear Register for cpu1_slv_local_arb_busecc_pend (access R/W1TC)
  [29] CPU0_MST_LOCAL_ARB_BUSECC_ENABLE_CLR — Interrupt Enable Clear Register for cpu0_mst_local_arb_busecc_pend (access R/W1TC)
  [28] CPU0_SLV_LOCAL_ARB_BUSECC_ENABLE_CLR — Interrupt Enable Clear Register for cpu0_slv_local_arb_busecc_pend (access R/W1TC)
  [27] EMIF0_MST_PIPE_BUSECC_ENABLE_CLR — Interrupt Enable Clear Register for emif0_mst_pipe_busecc_pend (access R/W1TC)
  [26] EMIF0_SLV_PIPE_BUSECC_ENABLE_CLR — Interrupt Enable Clear Register for emif0_slv_pipe_busecc_pend (access R/W1TC)
  [25] DRU1_MST_LOCAL_ARB_BUSECC_ENABLE_CLR — Interrupt Enable Clear Register for dru1_mst_local_arb_busecc_pend (access R/W1TC)
  [24] DRU0_MST_LOCAL_ARB_BUSECC_ENABLE_CLR — Interrupt Enable Clear Register for dru0_mst_local_arb_busecc_pend (access R/W1TC)
  [23] DRU1_SLV_LOCAL_ARB_BUSECC_ENABLE_CLR — Interrupt Enable Clear Register for dru1_slv_local_arb_busecc_pend (access R/W1TC)
  [22] DRU0_SLV_LOCAL_ARB_BUSECC_ENABLE_CLR — Interrupt Enable Clear Register for dru0_slv_local_arb_busecc_pend (access R/W1TC)
  [21] POSTARB_PIPE_CFG_BUSECC_ENABLE_CLR — Interrupt Enable Clear Register for postarb_pipe_cfg_busecc_pend (access R/W1TC)
  [20] MSMC_MMR_BUSECC_ENABLE_CLR — Interrupt Enable Clear Register for msmc_mmr_busecc_pend (access R/W1TC)
  [19] VBUSP_DMSC_CBASS_DRU0_FW_BRIDGE_DST_BUSECC_ENABLE_CLR — Interrupt Enable Clear Register for vbusp_dmsc_cbass_dru0_fw_bridge_dst_busecc_pend (access R/W1TC)
  [18] VBUSP_DMSC_CBASS_DRU0_MMR_FW_BRIDGE_DST_BUSECC_ENABLE_CLR — Interrupt Enable Clear Register for vbusp_dmsc_cbass_dru0_mmr_fw_bridge_dst_busecc_pend (access R/W1TC)
  [17] VBUSP_DRU0_MMR_FW_P2P_2_BUSECC_ENABLE_CLR — Interrupt Enable Clear Register for vbusp_dru0_mmr_fw_p2p_2_busecc_pend (access R/W1TC)
  [16] VBUSP_DRU0_MMR_FW_P2P_1_BUSECC_ENABLE_CLR — Interrupt Enable Clear Register for vbusp_dru0_mmr_fw_p2p_1_busecc_pend (access R/W1TC)
  [15] DRU0_RD_BUF_EDC_ENABLE_CLR — Interrupt Enable Clear Register for dru0_rd_buf_edc_pend (access R/W1TC)
  [14] DRU0_QUEUE_EDC_ENABLE_CLR — Interrupt Enable Clear Register for dru0_queue_edc_pend (access R/W1TC)
  [13] DRU0_ENG_EDC_ENABLE_CLR — Interrupt Enable Clear Register for dru0_eng_edc_pend (access R/W1TC)
  [12] DRU0_1_EDC_ENABLE_CLR — Interrupt Enable Clear Register for dru0_1_edc_pend (access R/W1TC)
  [11] DRU0_0_EDC_ENABLE_CLR — Interrupt Enable Clear Register for dru0_0_edc_pend (access R/W1TC)
  [10] DRU0_PSI_EDC_ENABLE_CLR — Interrupt Enable Clear Register for dru0_psi_edc_pend (access R/W1TC)
  [9] DRU0_MMR_FW_EDC_CTL_ENABLE_CLR — Interrupt Enable Clear Register for dru0_mmr_fw_edc_ctl_pend (access R/W1TC)
  [8] DRU0_CBASS_SCR_EDC_ENABLE_CLR — Interrupt Enable Clear Register for dru0_cbass_scr_edc_pend (access R/W1TC)
  [7] DRU0_CBASS_MMR_FW_CH_EDC_ENABLE_CLR — Interrupt Enable Clear Register for dru0_cbass_mmr_fw_ch_edc_pend (access R/W1TC)
  [6] DRU0_CBASS_MMR_FW_CH_BR_EDC_ENABLE_CLR — Interrupt Enable Clear Register for dru0_cbass_mmr_fw_ch_br_edc_pend (access R/W1TC)
  [5] DRU0_CBASS_MMR_EDC_ENABLE_CLR — Interrupt Enable Clear Register for dru0_cbass_mmr_edc_pend (access R/W1TC)
  [4] DRU0_CBASS_MMR_CFG_EDC_ENABLE_CLR — Interrupt Enable Clear Register for dru0_cbass_mmr_cfg_edc_pend (access R/W1TC)
  [3] DRU0_CBASS_MMR_BRDG_EDC_ENABLE_CLR — Interrupt Enable Clear Register for dru0_cbass_mmr_brdg_edc_pend (access R/W1TC)
  [2] DRU0_CBASS_EDC_CTRL_ENABLE_CLR — Interrupt Enable Clear Register for dru0_cbass_edc_ctrl_pend (access R/W1TC)
  [1] DRU0_CBASS_DMSC_SLV_BRDG_EDC_ENABLE_CLR — Interrupt Enable Clear Register for dru0_cbass_dmsc_slv_brdg_edc_pend (access R/W1TC)
  [0] DRU0_CBASS_DMSC_SCR_EDC_ENABLE_CLR — Interrupt Enable Clear Register for dru0_cbass_dmsc_scr_edc_pend (access R/W1TC)
0xC4 __VBUSP_MSMC_ECC_AGGR0__CFG_MSMC_ECC0_sec_enable_clr_reg1
  [31] RMW2_QUEUE_BUSECC_1_ENABLE_CLR — Interrupt Enable Clear Register for rmw2_queue_busecc_1_pend (access R/W1TC)
  [30] RMW2_QUEUE_BUSECC_0_ENABLE_CLR — Interrupt Enable Clear Register for rmw2_queue_busecc_0_pend (access R/W1TC)
  [29] RMW2_CACHE_TAG_PIPE_BUSECC_ENABLE_CLR — Interrupt Enable Clear Register for rmw2_cache_tag_pipe_busecc_pend (access R/W1TC)
  [28] RMW2_BUSECC_ENABLE_CLR — Interrupt Enable Clear Register for rmw2_busecc_pend (access R/W1TC)
  [27] DATARAM_BANK1_BUSECC_ENABLE_CLR — Interrupt Enable Clear Register for dataram_bank1_busecc_pend (access R/W1TC)
  [26] SRAM1_BUSECC_ENABLE_CLR — Interrupt Enable Clear Register for sram1_busecc_pend (access R/W1TC)
  [25] RMW1_SRAM_SF_PIPE_BUSECC_ENABLE_CLR — Interrupt Enable Clear Register for rmw1_sram_sf_pipe_busecc_pend (access R/W1TC)
  [24] RMW1_RMW_TAG_UPDATE_BUSECC_ENABLE_CLR — Interrupt Enable Clear Register for rmw1_rmw_tag_update_busecc_pend (access R/W1TC)
  [23] RMW1_QUEUE_BUSECC_2_ENABLE_CLR — Interrupt Enable Clear Register for rmw1_queue_busecc_2_pend (access R/W1TC)
  [22] RMW1_QUEUE_BUSECC_1_ENABLE_CLR — Interrupt Enable Clear Register for rmw1_queue_busecc_1_pend (access R/W1TC)
  [21] RMW1_QUEUE_BUSECC_0_ENABLE_CLR — Interrupt Enable Clear Register for rmw1_queue_busecc_0_pend (access R/W1TC)
  [20] RMW1_CACHE_TAG_PIPE_BUSECC_ENABLE_CLR — Interrupt Enable Clear Register for rmw1_cache_tag_pipe_busecc_pend (access R/W1TC)
  [19] RMW1_BUSECC_ENABLE_CLR — Interrupt Enable Clear Register for rmw1_busecc_pend (access R/W1TC)
  [18] DATARAM_BANK0_BUSECC_ENABLE_CLR — Interrupt Enable Clear Register for dataram_bank0_busecc_pend (access R/W1TC)
  [17] SRAM0_BUSECC_ENABLE_CLR — Interrupt Enable Clear Register for sram0_busecc_pend (access R/W1TC)
  [16] RMW0_SRAM_SF_PIPE_BUSECC_ENABLE_CLR — Interrupt Enable Clear Register for rmw0_sram_sf_pipe_busecc_pend (access R/W1TC)
  [15] RMW0_RMW_TAG_UPDATE_BUSECC_ENABLE_CLR — Interrupt Enable Clear Register for rmw0_rmw_tag_update_busecc_pend (access R/W1TC)
  [14] RMW0_QUEUE_BUSECC_2_ENABLE_CLR — Interrupt Enable Clear Register for rmw0_queue_busecc_2_pend (access R/W1TC)
  [13] RMW0_QUEUE_BUSECC_1_ENABLE_CLR — Interrupt Enable Clear Register for rmw0_queue_busecc_1_pend (access R/W1TC)
  [12] RMW0_QUEUE_BUSECC_0_ENABLE_CLR — Interrupt Enable Clear Register for rmw0_queue_busecc_0_pend (access R/W1TC)
  [11] RMW0_CACHE_TAG_PIPE_BUSECC_ENABLE_CLR — Interrupt Enable Clear Register for rmw0_cache_tag_pipe_busecc_pend (access R/W1TC)
  [10] RMW0_BUSECC_ENABLE_CLR — Interrupt Enable Clear Register for rmw0_busecc_pend (access R/W1TC)
  [9] EN_MSMC_P1_BUSECC_0_ENABLE_CLR — Interrupt Enable Clear Register for en_msmc_p1_busecc_0_pend (access R/W1TC)
  [8] EN_MSMC_P1_BUSECC_DATA_ENABLE_CLR — Interrupt Enable Clear Register for en_msmc_p1_busecc_data_pend (access R/W1TC)
  [7] EN_MSMC_P0_BUSECC_0_ENABLE_CLR — Interrupt Enable Clear Register for en_msmc_p0_busecc_0_pend (access R/W1TC)
  [6] EN_MSMC_P0_BUSECC_DATA_ENABLE_CLR — Interrupt Enable Clear Register for en_msmc_p0_busecc_data_pend (access R/W1TC)
  [5] CPU9_MST_LOCAL_ARB_BUSECC_ENABLE_CLR — Interrupt Enable Clear Register for cpu9_mst_local_arb_busecc_pend (access R/W1TC)
  [4] CPU9_SLV_LOCAL_ARB_BUSECC_ENABLE_CLR — Interrupt Enable Clear Register for cpu9_slv_local_arb_busecc_pend (access R/W1TC)
  [3] CPU8_MST_LOCAL_ARB_BUSECC_ENABLE_CLR — Interrupt Enable Clear Register for cpu8_mst_local_arb_busecc_pend (access R/W1TC)
  [2] CPU8_SLV_LOCAL_ARB_BUSECC_ENABLE_CLR — Interrupt Enable Clear Register for cpu8_slv_local_arb_busecc_pend (access R/W1TC)
  [1] CPU4_MST_LOCAL_ARB_BUSECC_ENABLE_CLR — Interrupt Enable Clear Register for cpu4_mst_local_arb_busecc_pend (access R/W1TC)
  [0] CPU4_SLV_LOCAL_ARB_BUSECC_ENABLE_CLR — Interrupt Enable Clear Register for cpu4_slv_local_arb_busecc_pend (access R/W1TC)
0xC8 __VBUSP_MSMC_ECC_AGGR0__CFG_MSMC_ECC0_sec_enable_clr_reg2
  [31] EMIF1_SLV_PIPE_BUSECC_ENABLE_CLR — Interrupt Enable Clear Register for emif1_slv_pipe_busecc_pend (access R/W1TC)
  [30] J7AHP_MSMC_CFG_WRAP_CBASS_J7AHP_MSMC_CFG_WRAP_CBASS_VBUSP_MSMC_ECC_AGGR0_P2P_BRIDGE_VBUSP_MSMC_ECC_AGGR0_BRIDGE_DST_BUSECC_ENABLE_CLR — Interrupt Enable Clear Register for j7ahp_msmc_cfg_wrap_cbass_j7ahp_msmc_cfg_wrap_cbass_vbusp_msmc_ecc_aggr0_p2p_bridge_vbusp_msmc_ecc_aggr0_bridge_dst_busecc_pend (access R/W1TC)
  [29] CLEC_SRAM_RAMECC_ENABLE_CLR — Interrupt Enable Clear Register for clec_sram_ramecc_pend (access R/W1TC)
  [28] MSMC_PSIL_PIPE_3_BUSECC_ENABLE_CLR — Interrupt Enable Clear Register for msmc_psil_pipe_3_busecc_pend (access R/W1TC)
  [27] MSMC_PSIL_PIPE_2_BUSECC_ENABLE_CLR — Interrupt Enable Clear Register for msmc_psil_pipe_2_busecc_pend (access R/W1TC)
  [26] MSMC_PSIL_PIPE_1_BUSECC_ENABLE_CLR — Interrupt Enable Clear Register for msmc_psil_pipe_1_busecc_pend (access R/W1TC)
  [n+13] MSMC_PSILSS_{n}_BUSECC_ENABLE_CLR (n=1..12) — Interrupt Enable Clear Register for msmc_psilss_{n}_busecc_pend (access R/W1TC)
  [13] DATARAM_BANK3_BUSECC_ENABLE_CLR — Interrupt Enable Clear Register for dataram_bank3_busecc_pend (access R/W1TC)
  [12] SRAM3_BUSECC_ENABLE_CLR — Interrupt Enable Clear Register for sram3_busecc_pend (access R/W1TC)
  [11] RMW3_SRAM_SF_PIPE_BUSECC_ENABLE_CLR — Interrupt Enable Clear Register for rmw3_sram_sf_pipe_busecc_pend (access R/W1TC)
  [10] RMW3_RMW_TAG_UPDATE_BUSECC_ENABLE_CLR — Interrupt Enable Clear Register for rmw3_rmw_tag_update_busecc_pend (access R/W1TC)
  [9] RMW3_QUEUE_BUSECC_2_ENABLE_CLR — Interrupt Enable Clear Register for rmw3_queue_busecc_2_pend (access R/W1TC)
  [8] RMW3_QUEUE_BUSECC_1_ENABLE_CLR — Interrupt Enable Clear Register for rmw3_queue_busecc_1_pend (access R/W1TC)
  [7] RMW3_QUEUE_BUSECC_0_ENABLE_CLR — Interrupt Enable Clear Register for rmw3_queue_busecc_0_pend (access R/W1TC)
  [6] RMW3_CACHE_TAG_PIPE_BUSECC_ENABLE_CLR — Interrupt Enable Clear Register for rmw3_cache_tag_pipe_busecc_pend (access R/W1TC)
  [5] RMW3_BUSECC_ENABLE_CLR — Interrupt Enable Clear Register for rmw3_busecc_pend (access R/W1TC)
  [4] DATARAM_BANK2_BUSECC_ENABLE_CLR — Interrupt Enable Clear Register for dataram_bank2_busecc_pend (access R/W1TC)
  [3] SRAM2_BUSECC_ENABLE_CLR — Interrupt Enable Clear Register for sram2_busecc_pend (access R/W1TC)
  [2] RMW2_SRAM_SF_PIPE_BUSECC_ENABLE_CLR — Interrupt Enable Clear Register for rmw2_sram_sf_pipe_busecc_pend (access R/W1TC)
  [1] RMW2_RMW_TAG_UPDATE_BUSECC_ENABLE_CLR — Interrupt Enable Clear Register for rmw2_rmw_tag_update_busecc_pend (access R/W1TC)
  [0] RMW2_QUEUE_BUSECC_2_ENABLE_CLR — Interrupt Enable Clear Register for rmw2_queue_busecc_2_pend (access R/W1TC)
0xCC __VBUSP_MSMC_ECC_AGGR0__CFG_MSMC_ECC0_sec_enable_clr_reg3
  [31] EN_MSMC_P1_BUSECC_WRITE_RESP_ENABLE_CLR — Interrupt Enable Clear Register for en_msmc_p1_busecc_write_resp_pend (access R/W1TC)
  [30] EN_MSMC_P1_BUSECC_WR_BARRIER_QUEUE_ENABLE_CLR — Interrupt Enable Clear Register for en_msmc_p1_busecc_wr_barrier_queue_pend (access R/W1TC)
  [29] EN_MSMC_P1_BUSECC_WACK_CID_QUEUE_ENABLE_CLR — Interrupt Enable Clear Register for en_msmc_p1_busecc_wack_cid_queue_pend (access R/W1TC)
  [28] EN_MSMC_P1_BUSECC_SNP_RESP_BUF_ENABLE_CLR — Interrupt Enable Clear Register for en_msmc_p1_busecc_snp_resp_buf_pend (access R/W1TC)
  [27] EN_MSMC_P1_BUSECC_SNP_DATA_BUF_ENABLE_CLR — Interrupt Enable Clear Register for en_msmc_p1_busecc_snp_data_buf_pend (access R/W1TC)
  [26] EN_MSMC_P1_BUSECC_SNOOP_CMD_ID_QUEUE_ENABLE_CLR — Interrupt Enable Clear Register for en_msmc_p1_busecc_snoop_cmd_id_queue_pend (access R/W1TC)
  [25] EN_MSMC_P1_BUSECC_RD_BARRIER_QUEUE_ENABLE_CLR — Interrupt Enable Clear Register for en_msmc_p1_busecc_rd_barrier_queue_pend (access R/W1TC)
  [24] EN_MSMC_P1_BUSECC_RACK_CID_QUEUE_ENABLE_CLR — Interrupt Enable Clear Register for en_msmc_p1_busecc_rack_cid_queue_pend (access R/W1TC)
  [23] VBUSP_DMSC_CBASS_CPAC1_FW_BRIDGE_DST_BUSECC_ENABLE_CLR — Interrupt Enable Clear Register for vbusp_dmsc_cbass_cpac1_fw_bridge_dst_busecc_pend (access R/W1TC)
  [22] EN_MSMC_P1_MMR_FW_EDC_CTL_ENABLE_CLR — Interrupt Enable Clear Register for en_msmc_p1_mmr_fw_edc_ctl_pend (access R/W1TC)
  [21] EN_MSMC_P0_BUSECC_MSMC_CMD_BUFFER_ENABLE_CLR — Interrupt Enable Clear Register for en_msmc_p0_busecc_msmc_cmd_buffer_pend (access R/W1TC)
  [20] EN_MSMC_P0_BUSECC_1_ENABLE_CLR — Interrupt Enable Clear Register for en_msmc_p0_busecc_1_pend (access R/W1TC)
  [19] EN_MSMC_P0_BUSECC_WRITE_RESP_ENABLE_CLR — Interrupt Enable Clear Register for en_msmc_p0_busecc_write_resp_pend (access R/W1TC)
  [18] EN_MSMC_P0_BUSECC_WR_BARRIER_QUEUE_ENABLE_CLR — Interrupt Enable Clear Register for en_msmc_p0_busecc_wr_barrier_queue_pend (access R/W1TC)
  [17] EN_MSMC_P0_BUSECC_WACK_CID_QUEUE_ENABLE_CLR — Interrupt Enable Clear Register for en_msmc_p0_busecc_wack_cid_queue_pend (access R/W1TC)
  [16] EN_MSMC_P0_BUSECC_SNP_RESP_BUF_ENABLE_CLR — Interrupt Enable Clear Register for en_msmc_p0_busecc_snp_resp_buf_pend (access R/W1TC)
  [15] EN_MSMC_P0_BUSECC_SNP_DATA_BUF_ENABLE_CLR — Interrupt Enable Clear Register for en_msmc_p0_busecc_snp_data_buf_pend (access R/W1TC)
  [14] EN_MSMC_P0_BUSECC_SNOOP_CMD_ID_QUEUE_ENABLE_CLR — Interrupt Enable Clear Register for en_msmc_p0_busecc_snoop_cmd_id_queue_pend (access R/W1TC)
  [13] EN_MSMC_P0_BUSECC_RD_BARRIER_QUEUE_ENABLE_CLR — Interrupt Enable Clear Register for en_msmc_p0_busecc_rd_barrier_queue_pend (access R/W1TC)
  [12] EN_MSMC_P0_BUSECC_RACK_CID_QUEUE_ENABLE_CLR — Interrupt Enable Clear Register for en_msmc_p0_busecc_rack_cid_queue_pend (access R/W1TC)
  [11] VBUSP_DMSC_CBASS_CPAC0_FW_BRIDGE_DST_BUSECC_ENABLE_CLR — Interrupt Enable Clear Register for vbusp_dmsc_cbass_cpac0_fw_bridge_dst_busecc_pend (access R/W1TC)
  [10] EN_MSMC_P0_MMR_FW_EDC_CTL_ENABLE_CLR — Interrupt Enable Clear Register for en_msmc_p0_mmr_fw_edc_ctl_pend (access R/W1TC)
  [9] CLEC_J7AHP_CLEC_EDC_CTRL_BUSECC_ENABLE_CLR — Interrupt Enable Clear Register for clec_j7ahp_clec_edc_ctrl_busecc_pend (access R/W1TC)
  [n+5] EMIF_{n}_VSAFE_SI_ENABLE_CLR (n=0..3) — Interrupt Enable Clear Register for emif_{n}_vsafe_si_pend (access R/W1TC)
  [4] EMIF3_MST_PIPE_BUSECC_ENABLE_CLR — Interrupt Enable Clear Register for emif3_mst_pipe_busecc_pend (access R/W1TC)
  [3] EMIF2_MST_PIPE_BUSECC_ENABLE_CLR — Interrupt Enable Clear Register for emif2_mst_pipe_busecc_pend (access R/W1TC)
  [2] EMIF1_MST_PIPE_BUSECC_ENABLE_CLR — Interrupt Enable Clear Register for emif1_mst_pipe_busecc_pend (access R/W1TC)
  [1] EMIF3_SLV_PIPE_BUSECC_ENABLE_CLR — Interrupt Enable Clear Register for emif3_slv_pipe_busecc_pend (access R/W1TC)
  [0] EMIF2_SLV_PIPE_BUSECC_ENABLE_CLR — Interrupt Enable Clear Register for emif2_slv_pipe_busecc_pend (access R/W1TC)
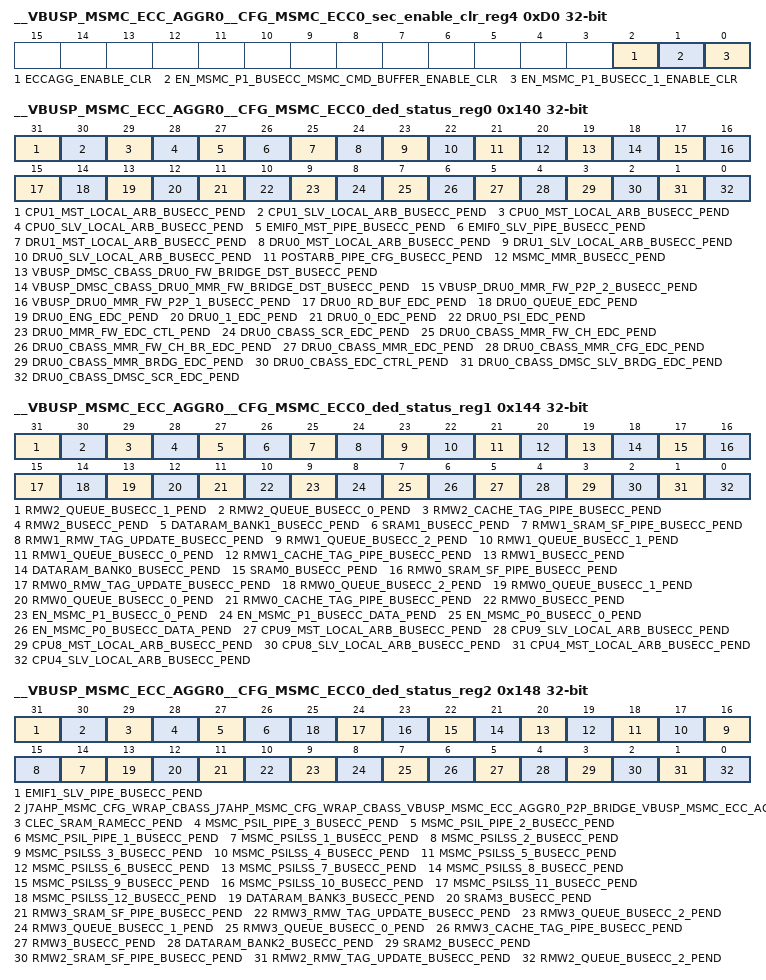
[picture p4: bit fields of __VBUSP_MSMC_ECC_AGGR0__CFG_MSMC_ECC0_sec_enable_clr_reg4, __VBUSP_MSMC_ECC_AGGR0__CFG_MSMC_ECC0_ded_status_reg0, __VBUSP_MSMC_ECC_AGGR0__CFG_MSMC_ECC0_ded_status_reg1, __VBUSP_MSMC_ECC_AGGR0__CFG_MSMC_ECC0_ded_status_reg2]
0xD0 __VBUSP_MSMC_ECC_AGGR0__CFG_MSMC_ECC0_sec_enable_clr_reg4
  [2] ECCAGG_ENABLE_CLR — Interrupt Enable Clear Register for eccagg_pend (access R/W1TC)
  [1] EN_MSMC_P1_BUSECC_MSMC_CMD_BUFFER_ENABLE_CLR — Interrupt Enable Clear Register for en_msmc_p1_busecc_msmc_cmd_buffer_pend (access R/W1TC)
  [0] EN_MSMC_P1_BUSECC_1_ENABLE_CLR — Interrupt Enable Clear Register for en_msmc_p1_busecc_1_pend (access R/W1TC)
0x13C __VBUSP_MSMC_ECC_AGGR0__CFG_MSMC_ECC0_ded_eoi_reg
  [0] EOI_WR — EOI Register (access R/W1TS)
0x140 __VBUSP_MSMC_ECC_AGGR0__CFG_MSMC_ECC0_ded_status_reg0
  fields as __VBUSP_MSMC_ECC_AGGR0__CFG_MSMC_ECC0_sec_status_reg0
0x144 __VBUSP_MSMC_ECC_AGGR0__CFG_MSMC_ECC0_ded_status_reg1
  fields as __VBUSP_MSMC_ECC_AGGR0__CFG_MSMC_ECC0_sec_status_reg1
0x148 __VBUSP_MSMC_ECC_AGGR0__CFG_MSMC_ECC0_ded_status_reg2
  fields as __VBUSP_MSMC_ECC_AGGR0__CFG_MSMC_ECC0_sec_status_reg2
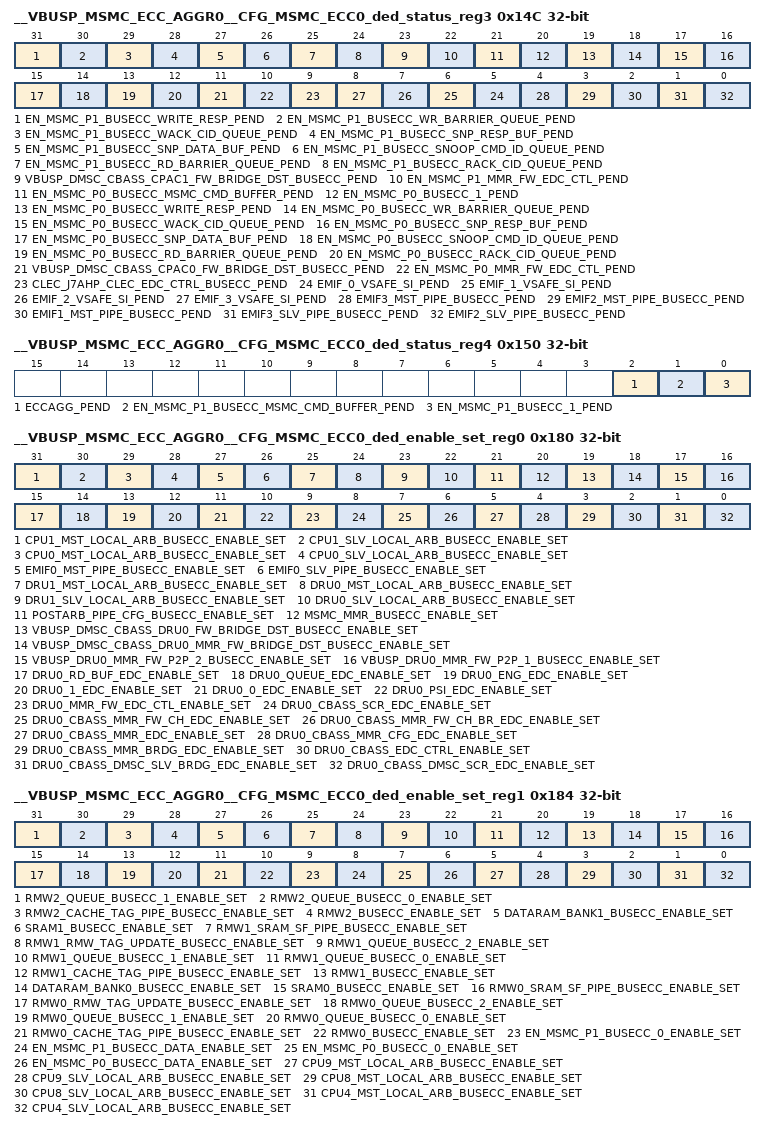
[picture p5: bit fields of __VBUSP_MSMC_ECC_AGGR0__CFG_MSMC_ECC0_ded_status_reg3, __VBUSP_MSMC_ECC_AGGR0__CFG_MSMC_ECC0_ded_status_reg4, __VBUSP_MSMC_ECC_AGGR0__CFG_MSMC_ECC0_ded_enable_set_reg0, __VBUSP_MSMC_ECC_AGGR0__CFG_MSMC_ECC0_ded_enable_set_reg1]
0x14C __VBUSP_MSMC_ECC_AGGR0__CFG_MSMC_ECC0_ded_status_reg3
  fields as __VBUSP_MSMC_ECC_AGGR0__CFG_MSMC_ECC0_sec_status_reg3
0x150 __VBUSP_MSMC_ECC_AGGR0__CFG_MSMC_ECC0_ded_status_reg4
  fields as __VBUSP_MSMC_ECC_AGGR0__CFG_MSMC_ECC0_sec_status_reg4
0x180 __VBUSP_MSMC_ECC_AGGR0__CFG_MSMC_ECC0_ded_enable_set_reg0
  fields as __VBUSP_MSMC_ECC_AGGR0__CFG_MSMC_ECC0_sec_enable_set_reg0
0x184 __VBUSP_MSMC_ECC_AGGR0__CFG_MSMC_ECC0_ded_enable_set_reg1
  fields as __VBUSP_MSMC_ECC_AGGR0__CFG_MSMC_ECC0_sec_enable_set_reg1
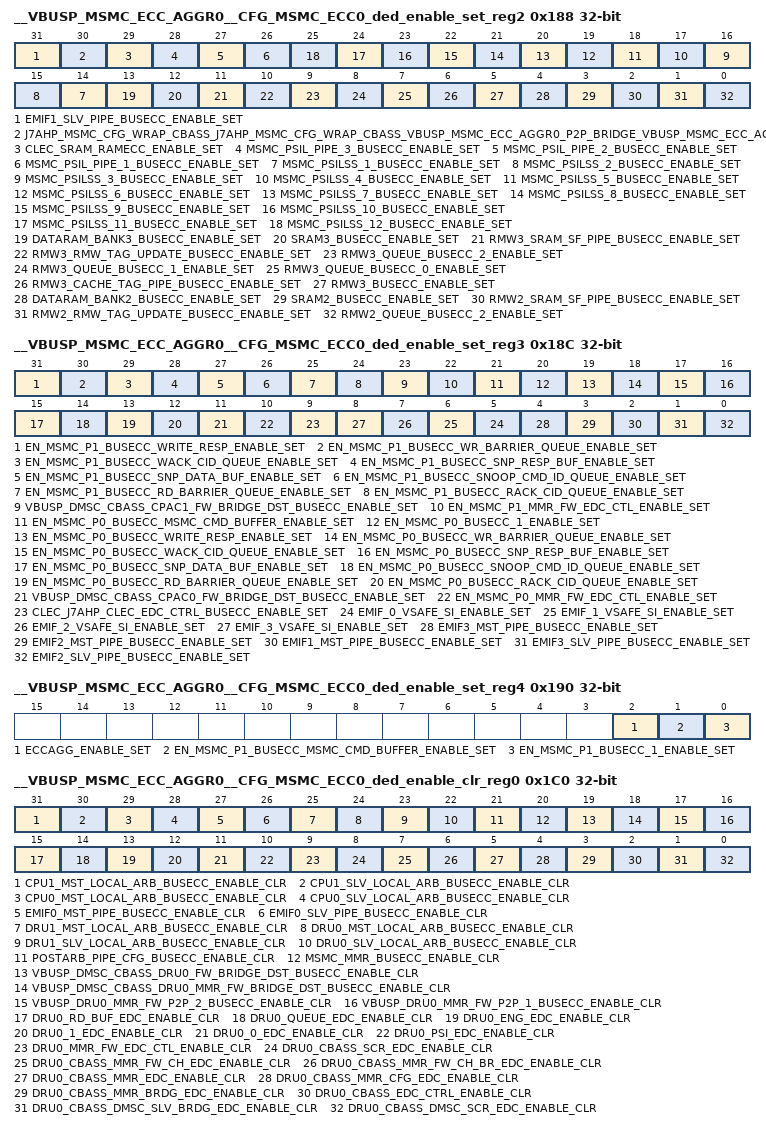
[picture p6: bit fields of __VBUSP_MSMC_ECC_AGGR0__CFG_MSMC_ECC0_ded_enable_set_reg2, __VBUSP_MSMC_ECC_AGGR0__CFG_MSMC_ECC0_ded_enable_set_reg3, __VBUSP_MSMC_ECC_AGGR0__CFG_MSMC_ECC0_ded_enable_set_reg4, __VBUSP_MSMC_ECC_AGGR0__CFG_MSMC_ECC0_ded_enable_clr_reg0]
0x188 __VBUSP_MSMC_ECC_AGGR0__CFG_MSMC_ECC0_ded_enable_set_reg2
  fields as __VBUSP_MSMC_ECC_AGGR0__CFG_MSMC_ECC0_sec_enable_set_reg2
0x18C __VBUSP_MSMC_ECC_AGGR0__CFG_MSMC_ECC0_ded_enable_set_reg3
  fields as __VBUSP_MSMC_ECC_AGGR0__CFG_MSMC_ECC0_sec_enable_set_reg3
0x190 __VBUSP_MSMC_ECC_AGGR0__CFG_MSMC_ECC0_ded_enable_set_reg4
  fields as __VBUSP_MSMC_ECC_AGGR0__CFG_MSMC_ECC0_sec_enable_set_reg4
0x1C0 __VBUSP_MSMC_ECC_AGGR0__CFG_MSMC_ECC0_ded_enable_clr_reg0
  fields as __VBUSP_MSMC_ECC_AGGR0__CFG_MSMC_ECC0_sec_enable_clr_reg0
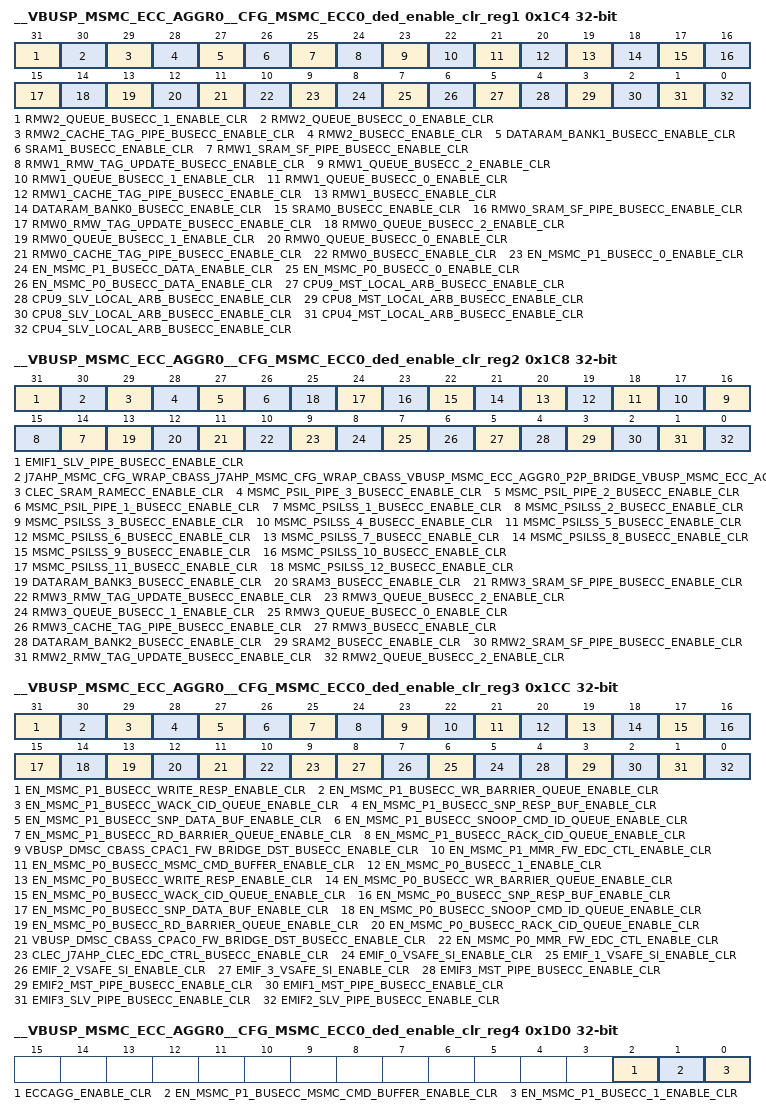
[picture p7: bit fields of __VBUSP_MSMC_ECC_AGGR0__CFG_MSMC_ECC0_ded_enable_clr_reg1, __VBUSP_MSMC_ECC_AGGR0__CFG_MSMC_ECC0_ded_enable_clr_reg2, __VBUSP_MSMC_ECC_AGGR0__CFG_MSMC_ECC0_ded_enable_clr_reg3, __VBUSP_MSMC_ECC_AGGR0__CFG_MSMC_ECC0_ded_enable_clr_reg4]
0x1C4 __VBUSP_MSMC_ECC_AGGR0__CFG_MSMC_ECC0_ded_enable_clr_reg1
  fields as __VBUSP_MSMC_ECC_AGGR0__CFG_MSMC_ECC0_sec_enable_clr_reg1
0x1C8 __VBUSP_MSMC_ECC_AGGR0__CFG_MSMC_ECC0_ded_enable_clr_reg2
  fields as __VBUSP_MSMC_ECC_AGGR0__CFG_MSMC_ECC0_sec_enable_clr_reg2
0x1CC __VBUSP_MSMC_ECC_AGGR0__CFG_MSMC_ECC0_ded_enable_clr_reg3
  fields as __VBUSP_MSMC_ECC_AGGR0__CFG_MSMC_ECC0_sec_enable_clr_reg3
0x1D0 __VBUSP_MSMC_ECC_AGGR0__CFG_MSMC_ECC0_ded_enable_clr_reg4
  fields as __VBUSP_MSMC_ECC_AGGR0__CFG_MSMC_ECC0_sec_enable_clr_reg4
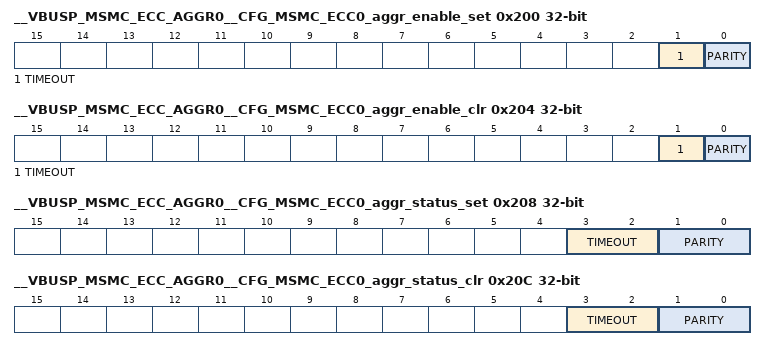
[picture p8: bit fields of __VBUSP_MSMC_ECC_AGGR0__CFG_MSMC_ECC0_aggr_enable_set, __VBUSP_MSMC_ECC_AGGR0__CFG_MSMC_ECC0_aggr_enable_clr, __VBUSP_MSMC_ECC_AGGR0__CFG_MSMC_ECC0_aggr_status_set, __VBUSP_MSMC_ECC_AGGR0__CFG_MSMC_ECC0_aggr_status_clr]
0x200 __VBUSP_MSMC_ECC_AGGR0__CFG_MSMC_ECC0_aggr_enable_set
  [1] TIMEOUT — interrupt enable set for svbus timeout errors (access R/W1TS)
  [0] PARITY — interrupt enable set for parity errors (access R/W1TS)
0x204 __VBUSP_MSMC_ECC_AGGR0__CFG_MSMC_ECC0_aggr_enable_clr
  [1] TIMEOUT — interrupt enable clear for svbus timeout errors (access R/W1TC)
  [0] PARITY — interrupt enable clear for parity errors (access R/W1TC)
0x208 __VBUSP_MSMC_ECC_AGGR0__CFG_MSMC_ECC0_aggr_status_set
  [3:2] TIMEOUT — interrupt status set for svbus timeout errors (access R/WI)
  [1:0] PARITY — interrupt status set for parity errors (access R/WI)
0x20C __VBUSP_MSMC_ECC_AGGR0__CFG_MSMC_ECC0_aggr_status_clr
  [3:2] TIMEOUT — interrupt status clear for svbus timeout errors (access R/WD)
  [1:0] PARITY — interrupt status clear for parity errors (access R/WD)
